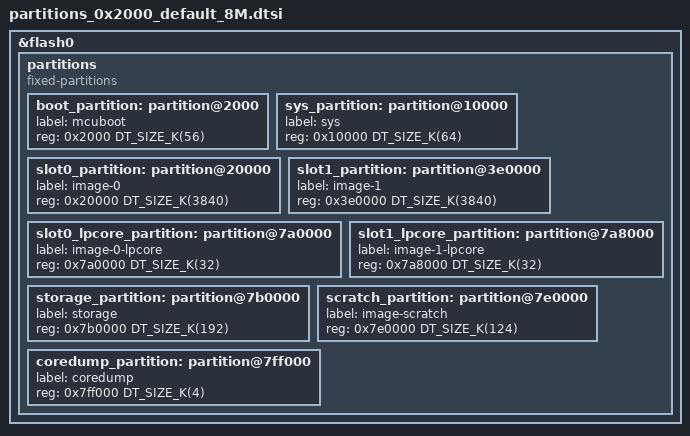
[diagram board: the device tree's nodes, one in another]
/*
 * Copyright (c) 2026 Espressif Systems (Shanghai) Co., Ltd.
 *
 * SPDX-License-Identifier: Apache-2.0
 *
 * ESP32-C5 partition table with 0x2000 boot offset.
 * The ROM reserves the first 2 flash sectors (8KB) for Key Manager.
 */

&flash0 {
	partitions {
		compatible = "fixed-partitions";
		#address-cells = <1>;
		#size-cells = <1>;

		boot_partition: partition@2000 {
			label = "mcuboot";
			reg = <0x2000 DT_SIZE_K(56)>;
		};

		sys_partition: partition@10000 {
			label = "sys";
			reg = <0x10000 DT_SIZE_K(64)>;
		};

		slot0_partition: partition@20000 {
			label = "image-0";
			reg = <0x20000 DT_SIZE_K(3840)>;
		};

		slot1_partition: partition@3e0000 {
			label = "image-1";
			reg = <0x3e0000 DT_SIZE_K(3840)>;
		};

		slot0_lpcore_partition: partition@7a0000 {
			label = "image-0-lpcore";
			reg = <0x7a0000 DT_SIZE_K(32)>;
		};

		slot1_lpcore_partition: partition@7a8000 {
			label = "image-1-lpcore";
			reg = <0x7a8000 DT_SIZE_K(32)>;
		};

		storage_partition: partition@7b0000 {
			label = "storage";
			reg = <0x7b0000 DT_SIZE_K(192)>;
		};

		scratch_partition: partition@7e0000 {
			label = "image-scratch";
			reg = <0x7e0000 DT_SIZE_K(124)>;
		};

		coredump_partition: partition@7ff000 {
			label = "coredump";
			reg = <0x7ff000 DT_SIZE_K(4)>;
		};
	};
};

/* Remaining flash size is 0kB
 * Last used address is 0x7FFFFF
 */
